# STM32L562 register map
File version: 1.1
Registers are 32-bit, read-write, reset 0x0 unless marked. A register's access mark holds for its fields unless they carry their own. Offsets are from the block's base; lines under a group give offsets from that group; [hi:lo] are bit positions; {n}, {i} and the like mark numbered series; 'fields as' and 'values as' point back to an identical list; <NAME> marks a mode.

## Memory map
0x40016000 DFSDM1 size 0x800 — Digital filter for sigma delta modulators

## Interrupts
102 DFSDM1_FLT0 (DFSDM1) — DFSDM1_FLT0 global interrupt
103 DFSDM1_FLT1 (DFSDM1) — DFSDM1_FLT1 global interrupt
104 DFSDM1_FLT2 (DFSDM1) — DFSDM1_FLT2 global interrupt
105 DFSDM1_FLT3 (DFSDM1) — DFSDM1_FLT3 global interrupt

## DFSDM1 — Digital filter for sigma delta modulators
Base 0x40016000
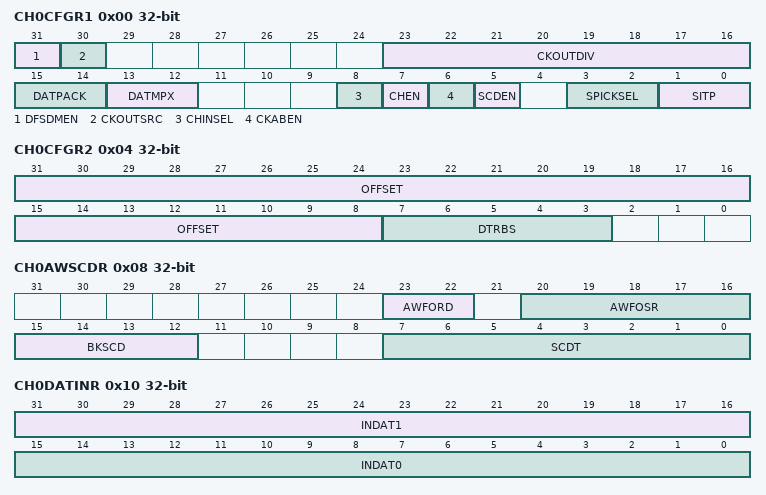
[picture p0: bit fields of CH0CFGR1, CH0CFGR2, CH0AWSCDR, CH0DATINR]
0x00 CH0CFGR1 — channel configuration y register
  [31] DFSDMEN, [30] CKOUTSRC, [23:16] CKOUTDIV, [15:14] DATPACK, [13:12] DATMPX, [8] CHINSEL, [7] CHEN, [6] CKABEN, [5] SCDEN, [3:2] SPICKSEL, [1:0] SITP
0x04 CH0CFGR2 — channel configuration y register
  [31:8] OFFSET, [7:3] DTRBS
0x08 CH0AWSCDR — analog watchdog and short-circuit detector register
  [23:22] AWFORD, [20:16] AWFOSR, [15:12] BKSCD, [7:0] SCDT
0x0C CH0WDATR — channel watchdog filter data register
  [15:0] WDATA
0x10 CH0DATINR — channel data input register
  [31:16] INDAT1, [15:0] INDAT0
0x14 CH0DLYR — DFSDM channel y delay register
  [5:0] PLSSKP — Pulses to skip for input data skipping function
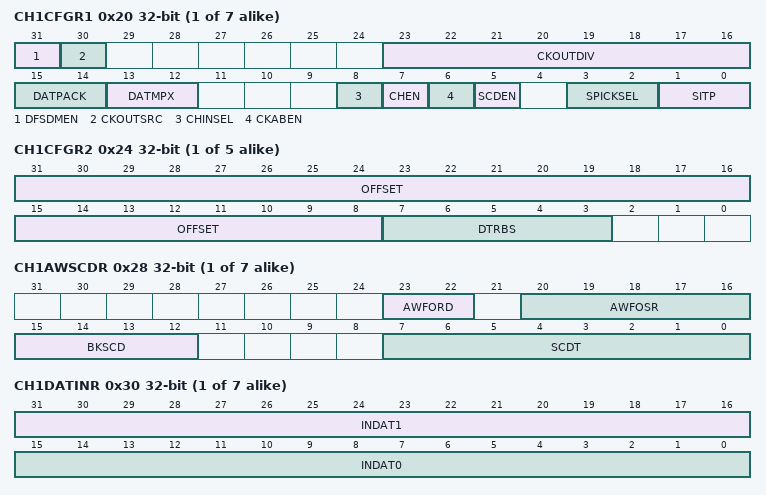
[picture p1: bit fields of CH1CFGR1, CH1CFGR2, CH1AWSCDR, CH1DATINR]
{0x0+0x20*i} CH{i}CFGR1 (i=1..7) — CHCFG{i}R1
  [31] DFSDMEN — Global enable for DFSDM interface
  [30] CKOUTSRC — Output serial clock source selection
  [23:16] CKOUTDIV — Output serial clock divider
  [15:14] DATPACK
  [13:12] DATMPX
  [8] CHINSEL
  [7] CHEN
  [6] CKABEN
  [5] SCDEN
  [3:2] SPICKSEL
  [1:0] SITP
{0x4+0x20*i} CH{i}CFGR2 (i=1..5) — CHCFG{i}R2
  [31:8] OFFSET, [7:3] DTRBS
{0x8+0x20*i} CH{i}AWSCDR (i=1..7) — AWSCD{i}R
  [23:22] AWFORD, [20:16] AWFOSR, [15:12] BKSCD, [7:0] SCDT
{0xC+0x20*i} CH{i}WDATR (i=1..7) — CHWDAT{i}R
  [15:0] WDATA
{0x10+0x20*i} CH{i}DATINR (i=1..7) — CHDATIN{i}R
  [31:16] INDAT1, [15:0] INDAT0
{0x14+0x20*i} CH{i}DLYR (i=1..4) — DFSDM channel y delay register
  [5:0] PLSSKP
0xB4 CH5DLYR — DFSDM channel y delay register
  [5:0] PLSSKP — read-only
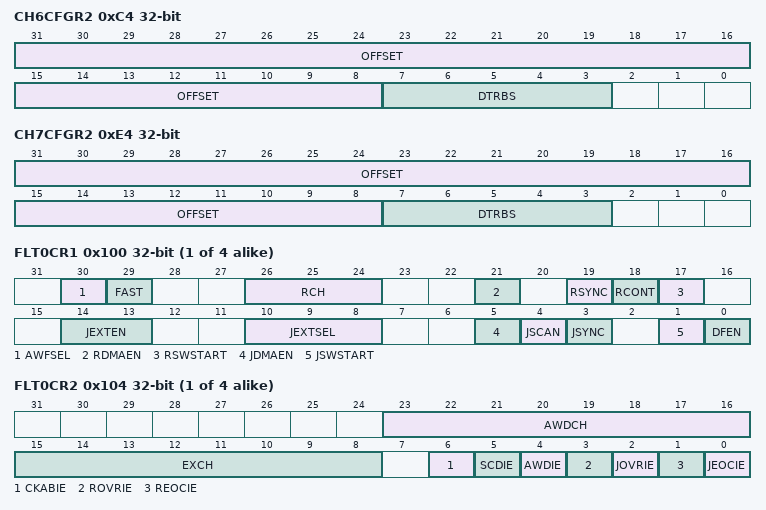
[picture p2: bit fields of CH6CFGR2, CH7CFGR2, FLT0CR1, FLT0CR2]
0xC4 CH6CFGR2
  [31:8] OFFSET, [7:3] DTRBS
0xD4 CH6DLYR — DFSDM channel y delay register
  [5:0] PLSSKP
0xE4 CH7CFGR2 — CHCFG7R2
  [31:8] OFFSET, [7:3] DTRBS
0xF4 CH7DLYR — DFSDM channel y delay register
  [5:0] PLSSKP
{0x100+0x80*i} FLT{i}CR1 (i=0..3) — control register 1
  [30] AWFSEL — Analog watchdog fast mode select
  [29] FAST — Fast conversion mode selection for regular conversions
  [26:24] RCH — Regular channel selection
  [21] RDMAEN — DMA channel enabled to read data for the regular conversion
  [19] RSYNC — Launch regular conversion synchronously with DFSDM0
  [18] RCONT — Continuous mode selection for regular conversions
  [17] RSWSTART — Software start of a conversion on the regular channel
  [14:13] JEXTEN — Trigger enable and trigger edge selection for injected conversions
  [10:8] JEXTSEL — Trigger signal selection for launching injected conversions
  [5] JDMAEN — DMA channel enabled to read data for the injected channel group
  [4] JSCAN — Scanning conversion mode for injected conversions
  [3] JSYNC — Launch an injected conversion synchronously with the DFSDM0 JSWSTART trigger
  [1] JSWSTART — Start a conversion of the injected group of channels
  [0] DFEN — DFSDM enable
{0x104+0x80*i} FLT{i}CR2 (i=0..3) — control register 2
  [23:16] AWDCH — Analog watchdog channel selection
  [15:8] EXCH — Extremes detector channel selection
  [6] CKABIE — Clock absence interrupt enable
  [5] SCDIE — Short-circuit detector interrupt enable
  [4] AWDIE — Analog watchdog interrupt enable
  [3] ROVRIE — Regular data overrun interrupt enable
  [2] JOVRIE — Injected data overrun interrupt enable
  [1] REOCIE — Regular end of conversion interrupt enable
  [0] JEOCIE — Injected end of conversion interrupt enable
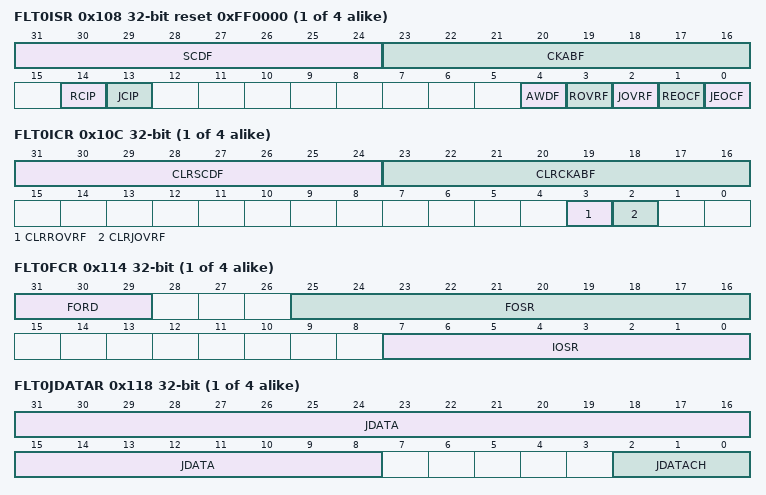
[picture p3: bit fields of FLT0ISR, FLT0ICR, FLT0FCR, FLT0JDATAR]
{0x108+0x80*i} FLT{i}ISR ro reset 0xFF0000 (i=0..3) — interrupt and status register
  [31:24] SCDF — short-circuit detector flag
  [23:16] CKABF — Clock absence flag
  [14] RCIP — Regular conversion in progress status
  [13] JCIP — Injected conversion in progress status
  [4] AWDF — Analog watchdog
  [3] ROVRF — Regular conversion overrun flag
  [2] JOVRF — Injected conversion overrun flag
  [1] REOCF — End of regular conversion flag
  [0] JEOCF — End of injected conversion flag
{0x10C+0x80*i} FLT{i}ICR (i=0..3) — interrupt flag clear register
  [31:24] CLRSCDF — Clear the short-circuit detector flag
  [23:16] CLRCKABF — Clear the clock absence flag
  [3] CLRROVRF — Clear the regular conversion overrun flag
  [2] CLRJOVRF — Clear the injected conversion overrun flag
{0x110+0x80*i} FLT{i}JCHGR reset 0x1 (i=0..3) — injected channel group selection register
  [7:0] JCHG — Injected channel group selection
{0x114+0x80*i} FLT{i}FCR (i=0..3) — filter control register
  [31:29] FORD — Sinc filter order
  [25:16] FOSR — Sinc filter oversampling ratio (decimation rate)
  [7:0] IOSR — Integrator oversampling ratio (averaging length)
{0x118+0x80*i} FLT{i}JDATAR ro (i=0..3) — data register for injected group
  [31:8] JDATA — Injected group conversion data
  [2:0] JDATACH — Injected channel most recently converted
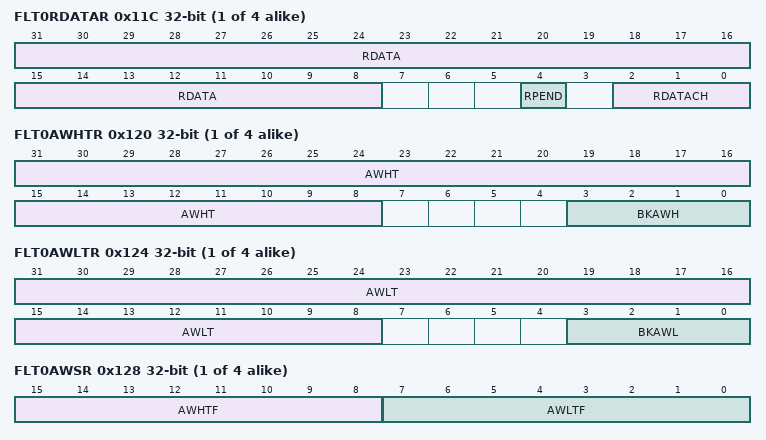
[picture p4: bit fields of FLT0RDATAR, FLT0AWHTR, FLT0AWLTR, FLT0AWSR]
{0x11C+0x80*i} FLT{i}RDATAR ro (i=0..3) — data register for the regular channel
  [31:8] RDATA — Regular channel conversion data
  [4] RPEND — Regular channel pending data
  [2:0] RDATACH — Regular channel most recently converted
{0x120+0x80*i} FLT{i}AWHTR (i=0..3) — analog watchdog high threshold register
  [31:8] AWHT — Analog watchdog high threshold
  [3:0] BKAWH — Break signal assignment to analog watchdog high threshold event
{0x124+0x80*i} FLT{i}AWLTR (i=0..3) — analog watchdog low threshold register
  [31:8] AWLT — Analog watchdog low threshold
  [3:0] BKAWL — Break signal assignment to analog watchdog low threshold event
{0x128+0x80*i} FLT{i}AWSR ro (i=0..3) — analog watchdog status register
  [15:8] AWHTF — Analog watchdog high threshold flag
  [7:0] AWLTF — Analog watchdog low threshold flag
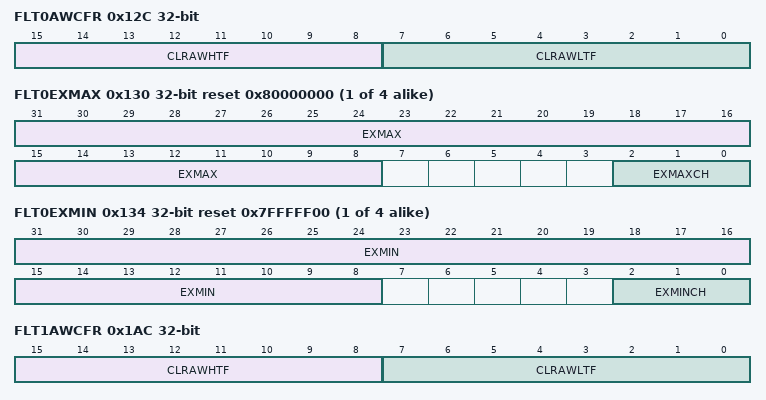
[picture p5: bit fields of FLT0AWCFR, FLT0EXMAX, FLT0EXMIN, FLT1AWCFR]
0x12C FLT0AWCFR — analog watchdog clear flag register
  [15:8] CLRAWHTF — Clear the analog watchdog high threshold flag
  [7:0] CLRAWLTF — Clear the analog watchdog low threshold flag
{0x130+0x80*i} FLT{i}EXMAX ro reset 0x80000000 (i=0..3) — Extremes detector maximum register
  [31:8] EXMAX — Extremes detector maximum value
  [2:0] EXMAXCH — Extremes detector maximum data channel
{0x134+0x80*i} FLT{i}EXMIN ro reset 0x7FFFFF00 (i=0..3) — Extremes detector minimum register
  [31:8] EXMIN
  [2:0] EXMINCH — Extremes detector minimum data channel
{0x138+0x80*i} FLT{i}CNVTIMR ro (i=0..3) — conversion timer register
  [31:4] CNVCNT — 28-bit timer counting conversion time t = CNVCNT[27:0] / fDFSDM_CKIN
0x1AC FLT1AWCFR (alternate view of FLT1AWHTR) — analog watchdog clear flag register
  fields as FLT0AWCFR
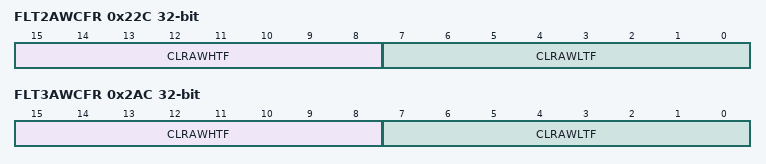
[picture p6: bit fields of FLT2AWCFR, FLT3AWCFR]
0x22C FLT2AWCFR — analog watchdog clear flag register
  fields as FLT0AWCFR
0x2AC FLT3AWCFR — analog watchdog clear flag register
  fields as FLT0AWCFR
